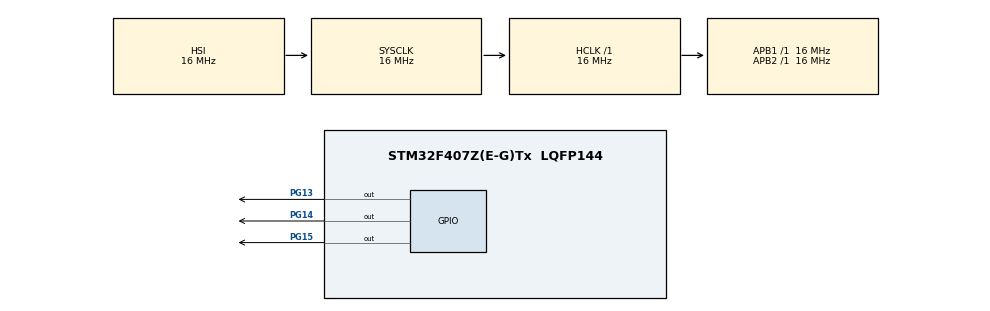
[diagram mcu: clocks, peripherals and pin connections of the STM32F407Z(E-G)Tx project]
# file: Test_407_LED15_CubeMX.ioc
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Mcu.Family=STM32F4
Mcu.Name=STM32F407Z(E-G)Tx
Mcu.Package=LQFP144
NVIC.PriorityGroup=NVIC_PRIORITYGROUP_4
PG13.Signal=GPIO_Output
PG14.Signal=GPIO_Output
PG15.Signal=GPIO_Output
PH0-OSC_IN.Mode=HSE-External-Oscillator
PH0-OSC_IN.Signal=RCC_OSC_IN
PH1-OSC_OUT.Mode=HSE-External-Oscillator
PH1-OSC_OUT.Signal=RCC_OSC_OUT
ProjectManager.HeapSize=0x200
ProjectManager.StackSize=0x400
ProjectManager.TargetToolchain=SW4STM32
RCC.AHBFreq_Value=16000000
RCC.APB1Freq_Value=16000000
RCC.APB2Freq_Value=16000000
RCC.CortexFreq_Value=16000000
RCC.HSE_VALUE=25000000
RCC.HSI_VALUE=16000000
RCC.LSE_VALUE=32768
RCC.SYSCLKFreq_VALUE=16000000
RCC.VCOOutputFreq_Value=192000000
board=custom

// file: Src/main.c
/* USER CODE BEGIN Header */
/**
  ******************************************************************************
  * @file           : main.c
  * @brief          : Main program body
  ******************************************************************************
  ** This notice applies to any and all portions of this file
  * that are not between comment pairs USER CODE BEGIN and
  * USER CODE END. Other portions of this file, whether
  * inserted by the user or by software development tools
  * are owned by their respective copyright owners.
  *
  * COPYRIGHT(c) 2018 STMicroelectronics
  *
  * Redistribution and use in source and binary forms, with or without modification,
  * are permitted provided that the following conditions are met:
  *   1. Redistributions of source code must retain the above copyright notice,
  *      this list of conditions and the following disclaimer.
  *   2. Redistributions in binary form must reproduce the above copyright notice,
  *      this list of conditions and the following disclaimer in the documentation
  *      and/or other materials provided with the distribution.
  *   3. Neither the name of STMicroelectronics nor the names of its contributors
  *      may be used to endorse or promote products derived from this software
  *      without specific prior written permission.
  *
  * THIS SOFTWARE IS PROVIDED BY THE COPYRIGHT HOLDERS AND CONTRIBUTORS "AS IS"
  * AND ANY EXPRESS OR IMPLIED WARRANTIES, INCLUDING, BUT NOT LIMITED TO, THE
  * IMPLIED WARRANTIES OF MERCHANTABILITY AND FITNESS FOR A PARTICULAR PURPOSE ARE
  * DISCLAIMED. IN NO EVENT SHALL THE COPYRIGHT HOLDER OR CONTRIBUTORS BE LIABLE
  * FOR ANY DIRECT, INDIRECT, INCIDENTAL, SPECIAL, EXEMPLARY, OR CONSEQUENTIAL
  * DAMAGES (INCLUDING, BUT NOT LIMITED TO, PROCUREMENT OF SUBSTITUTE GOODS OR
  * SERVICES; LOSS OF USE, DATA, OR PROFITS; OR BUSINESS INTERRUPTION) HOWEVER
  * CAUSED AND ON ANY THEORY OF LIABILITY, WHETHER IN CONTRACT, STRICT LIABILITY,
  * OR TORT (INCLUDING NEGLIGENCE OR OTHERWISE) ARISING IN ANY WAY OUT OF THE USE
  * OF THIS SOFTWARE, EVEN IF ADVISED OF THE POSSIBILITY OF SUCH DAMAGE.
  *
  ******************************************************************************
  */
/* USER CODE END Header */

#include "main.h"

void SystemClock_Config(void);
static void MX_GPIO_Init(void);

/* USER CODE BEGIN 0 */

#ifdef __cplusplus
extern "C"
#endif
/* USER CODE END 0 */

int main(void)
{

  /* MCU Configuration--------------------------------------------------------*/

  /* Reset of all peripherals, Initializes the Flash interface and the Systick. */
  HAL_Init();

  /* Configure the system clock */
  SystemClock_Config();

  /* Initialize all configured peripherals */
  MX_GPIO_Init();

  /* Infinite loop */
  while (1)
  {

    /* USER CODE BEGIN 3 */
	  for (;;)
	  {
		  HAL_GPIO_WritePin(GPIOG, GPIO_PIN_15, GPIO_PIN_SET);
		  HAL_GPIO_WritePin(GPIOG, GPIO_PIN_13, GPIO_PIN_RESET);
		  HAL_Delay(300);
		  HAL_GPIO_WritePin(GPIOG, GPIO_PIN_15, GPIO_PIN_RESET);
		  HAL_GPIO_WritePin(GPIOG, GPIO_PIN_13, GPIO_PIN_SET);
		  HAL_Delay(300);
	  }
  }
  /* USER CODE END 3 */
}

void SystemClock_Config(void)
{
  RCC_OscInitTypeDef RCC_OscInitStruct = {0};
  RCC_ClkInitTypeDef RCC_ClkInitStruct = {0};

  /**Configure the main internal regulator output voltage
  */
  __HAL_RCC_PWR_CLK_ENABLE();
  __HAL_PWR_VOLTAGESCALING_CONFIG(PWR_REGULATOR_VOLTAGE_SCALE1);
  /**Initializes the CPU, AHB and APB busses clocks
  */
  RCC_OscInitStruct.OscillatorType = RCC_OSCILLATORTYPE_HSI;
  RCC_OscInitStruct.HSIState = RCC_HSI_ON;
  RCC_OscInitStruct.HSICalibrationValue = RCC_HSICALIBRATION_DEFAULT;
  RCC_OscInitStruct.PLL.PLLState = RCC_PLL_NONE;
  if (HAL_RCC_OscConfig(&RCC_OscInitStruct) != HAL_OK)
  {
    Error_Handler();
  }
  /**Initializes the CPU, AHB and APB busses clocks
  */
  RCC_ClkInitStruct.ClockType = RCC_CLOCKTYPE_HCLK|RCC_CLOCKTYPE_SYSCLK
                              |RCC_CLOCKTYPE_PCLK1|RCC_CLOCKTYPE_PCLK2;
  RCC_ClkInitStruct.SYSCLKSource = RCC_SYSCLKSOURCE_HSI;
  RCC_ClkInitStruct.AHBCLKDivider = RCC_SYSCLK_DIV1;
  RCC_ClkInitStruct.APB1CLKDivider = RCC_HCLK_DIV1;
  RCC_ClkInitStruct.APB2CLKDivider = RCC_HCLK_DIV1;

  if (HAL_RCC_ClockConfig(&RCC_ClkInitStruct, FLASH_LATENCY_0) != HAL_OK)
  {
    Error_Handler();
  }
}

static void MX_GPIO_Init(void)
{
  GPIO_InitTypeDef GPIO_InitStruct = {0};

  /* GPIO Ports Clock Enable */
  __HAL_RCC_GPIOH_CLK_ENABLE();
  __HAL_RCC_GPIOG_CLK_ENABLE();

  /*Configure GPIO pin Output Level */
  HAL_GPIO_WritePin(GPIOG, GPIO_PIN_13|GPIO_PIN_14|GPIO_PIN_15, GPIO_PIN_RESET);

  /*Configure GPIO pins : PG13 PG14 PG15 */
  GPIO_InitStruct.Pin = GPIO_PIN_13|GPIO_PIN_14|GPIO_PIN_15;
  GPIO_InitStruct.Mode = GPIO_MODE_OUTPUT_PP;
  GPIO_InitStruct.Pull = GPIO_NOPULL;
  GPIO_InitStruct.Speed = GPIO_SPEED_FREQ_LOW;
  HAL_GPIO_Init(GPIOG, &GPIO_InitStruct);

}

void Error_Handler(void)
{
}

/************************ (C) COPYRIGHT STMicroelectronics *****END OF FILE****/
